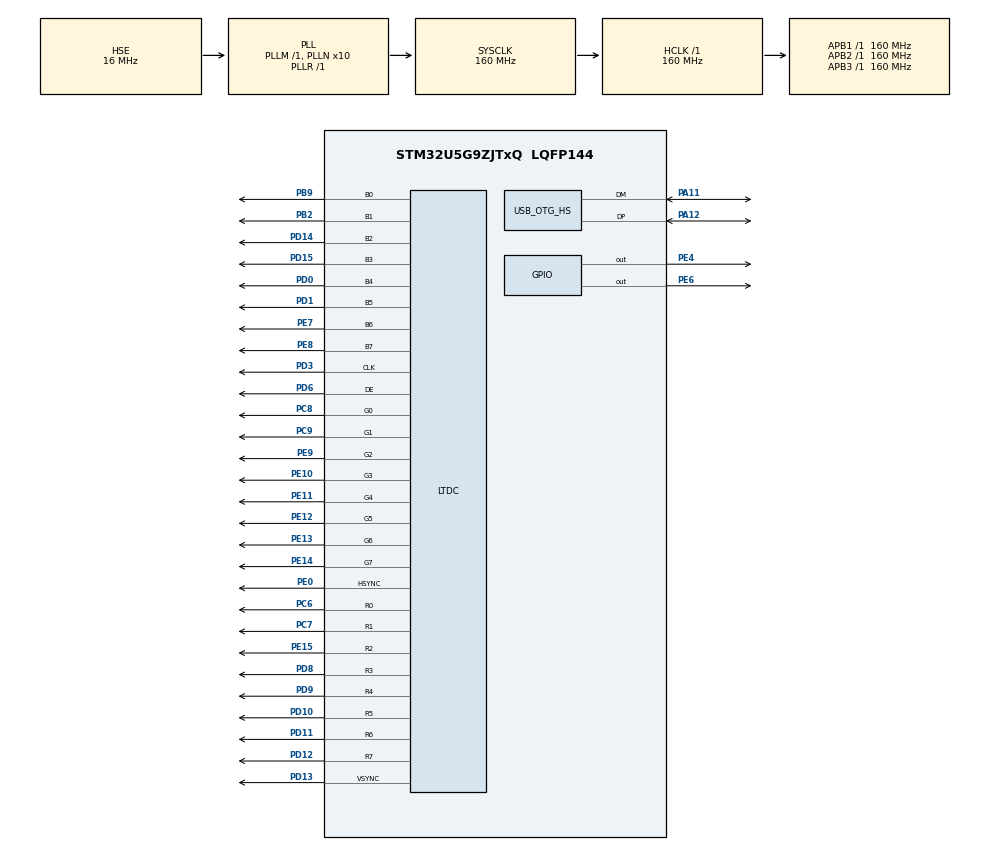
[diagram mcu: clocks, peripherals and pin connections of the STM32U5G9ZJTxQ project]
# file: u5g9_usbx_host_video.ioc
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CORTEX_M33_NS.userName=CORTEX_M33
LTDC.ActiveW=800
LTDC.Alpha0_L0=255
LTDC.Alpha_L0=255
LTDC.FBStartAdress_L0=0x300D0000
LTDC.Green_L0=255
LTDC.HBP=8
LTDC.HFP=8
LTDC.HSync=4
LTDC.ImageHeight_L0=240
LTDC.ImageWidth_L0=320
LTDC.Layers=0
LTDC.PixelFormat_L0=LTDC_PIXEL_FORMAT_RGB888
LTDC.VBP=8
LTDC.VFP=8
LTDC.WindowX1_L0=320
LTDC.WindowY1_L0=240
Mcu.Family=STM32U5
Mcu.Name=STM32U5G9ZJTxQ
Mcu.Package=LQFP144
NVIC.OTG_HS_IRQn=true\:0\:0\:false\:false\:true\:true\:true\:true
NVIC.PriorityGroup=NVIC_PRIORITYGROUP_4
PA11.Mode=Internal_Phy_Host
PA11.Signal=USB_OTG_HS_DM
PA12.Mode=Internal_Phy_Host
PA12.Signal=USB_OTG_HS_DP
PB2.Mode=RGB888
PB2.Signal=LTDC_B1
PB9.Mode=RGB888
PB9.Signal=LTDC_B0
PC6.Mode=RGB888
PC6.Signal=LTDC_R0
PC7.Mode=RGB888
PC7.Signal=LTDC_R1
PC8.Mode=RGB888
PC8.Signal=LTDC_G0
PC9.Mode=RGB888
PC9.Signal=LTDC_G1
PD0.Mode=RGB888
PD0.Signal=LTDC_B4
PD1.Mode=RGB888
PD1.Signal=LTDC_B5
PD10.Mode=RGB888
PD10.Signal=LTDC_R5
PD11.Mode=RGB888
PD11.Signal=LTDC_R6
PD12.Mode=RGB888
PD12.Signal=LTDC_R7
PD13.Mode=RGB888
PD13.Signal=LTDC_VSYNC
PD14.Mode=RGB888
PD14.Signal=LTDC_B2
PD15.Mode=RGB888
PD15.Signal=LTDC_B3
PD3.Mode=RGB888
PD3.Signal=LTDC_CLK
PD6.Mode=RGB888
PD6.Signal=LTDC_DE
PD8.Mode=RGB888
PD8.Signal=LTDC_R3
PD9.Mode=RGB888
PD9.Signal=LTDC_R4
PE0.Mode=RGB888
PE0.Signal=LTDC_HSYNC
PE10.Mode=RGB888
PE10.Signal=LTDC_G3
PE11.Mode=RGB888
PE11.Signal=LTDC_G4
PE12.Mode=RGB888
PE12.Signal=LTDC_G5
PE13.Mode=RGB888
PE13.Signal=LTDC_G6
PE14.Mode=RGB888
PE14.Signal=LTDC_G7
PE15.Mode=RGB888
PE15.Signal=LTDC_R2
PE4.PinState=GPIO_PIN_SET
PE4.Signal=GPIO_Output
PE6.GPIO_ModeDefaultOutputPP=GPIO_MODE_OUTPUT_OD
PE6.GPIO_PuPd=GPIO_NOPULL
PE6.PinState=GPIO_PIN_SET
PE6.Signal=GPIO_Output
PE7.Mode=RGB888
PE7.Signal=LTDC_B6
PE8.Mode=RGB888
PE8.Signal=LTDC_B7
PE9.Mode=RGB888
PE9.Signal=LTDC_G2
PH0-OSC_IN\ (PH0).Mode=HSE-External-Oscillator
PH0-OSC_IN\ (PH0).Signal=RCC_OSC_IN
PH1-OSC_OUT\ (PH1).Mode=HSE-External-Oscillator
PH1-OSC_OUT\ (PH1).Signal=RCC_OSC_OUT
ProjectManager.HeapSize=0x200
ProjectManager.StackSize=0x400
ProjectManager.TargetToolchain=STM32CubeIDE
RCC.ADCFreq_Value=16000000
RCC.AHBFreq_Value=160000000
RCC.APB1Freq_Value=160000000
RCC.APB1TimFreq_Value=160000000
RCC.APB2Freq_Value=160000000
RCC.APB2TimFreq_Value=160000000
RCC.APB3Freq_Value=160000000
RCC.CortexFreq_Value=160000000
RCC.EPOD_VALUE=16000000
RCC.HCLKFreq_Value=160000000
RCC.HSE_VALUE=16000000
RCC.HSI48_VALUE=48000000
RCC.HSI_VALUE=16000000
RCC.LSE_VALUE=32768
RCC.LSIDIV_VALUE=32000
RCC.MSI_VALUE=4000000
RCC.PLL1R=1
RCC.PLL2FRACN=0
RCC.PLL2M=3
RCC.PLL2N=100
RCC.PLL2R=21
RCC.PLL2Source=RCC_PLLSOURCE_HSE
RCC.PLLN=10
RCC.PLLSourceVirtual=RCC_PLLSOURCE_HSE
RCC.SYSCLKFreq_VALUE=160000000
RCC.SYSCLKSource=RCC_SYSCLKSOURCE_PLLCLK
RCC.USBPHYCLockSelection=RCC_USBPHYCLKSOURCE_HSE
RCC.VCOOutputFreq_Value=160000000
USBX.BSP.number=1
USBX.Core_System=1
USBX.USBX_HOST_SYS_SIZE=49152
USBX.UX_HOST_APP_MEM_POOL_SIZE_STANDALONE=65536
USBX.UX_Host_Controller=1
USBX.UX_Host_CoreStack=1
USBX.UX_Host_class_VIDEO=1
USBX.UX_MAX_HCD=2
USBX0.BSP.STBoard=false
USBX0.BSP.api=Unknown
USBX0.BSP.instance=USB_OTG_HS
USBX0.BSP.ip=USB_OTG_HS
USBX0.BSP.mode=Host_Only
USBX0.BSP.name=USBHost
USBX0.BSP.solution=USB_OTG_HS
USB_OTG_HS.VirtualMode=Host_HS
USB_OTG_HS.use_external_vbus=DISABLE
VP_LPBAMQUEUE_VS_QUEUE.Mode=QUEUEMODE
VP_LPBAM_VS_SIG1.Mode=SmartRun
VP_LPBAM_VS_SIG4.Mode=LPDMA1
VP_MEMORYMAP_VS_MEMORYMAP.Mode=CurAppReg
VP_PWR_VS_SECSignals.Mode=Security/Privilege
VP_USBX_Core_System.Mode=Core_System
VP_USBX_UX\ Host\ Controller_HS.Mode=UX_Host_Controller_HS
VP_USBX_UX\ Host\ CoreStack_HS.Mode=UX_Host_CoreStack_HS
VP_USBX_UX\ Host\ VIDEO_HS.Mode=UX_Host_class_VIDEO_HS
board=custom

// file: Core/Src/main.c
/* USER CODE BEGIN Header */
/**
  ******************************************************************************
  * @file           : main.c
  * @brief          : Main program body
  ******************************************************************************
  * @attention
  *
  * Copyright (c) 2024 STMicroelectronics.
  * All rights reserved.
  *
  * This software is licensed under terms that can be found in the LICENSE file
  * in the root directory of this software component.
  * If no LICENSE file comes with this software, it is provided AS-IS.
  *
  ******************************************************************************
  */
/* USER CODE END Header */
#include "main.h"
#include "app_usbx_host.h"

LTDC_HandleTypeDef hltdc;

HCD_HandleTypeDef hhcd_USB_OTG_HS;

void SystemClock_Config(void);
static void MX_GPIO_Init(void);
static void MX_USB_OTG_HS_HCD_Init(void);
static void MX_LTDC_Init(void);

int main(void)
{

  /* USER CODE BEGIN 1 */
memset(0x300D0000,0,320*240*3);
  /* USER CODE END 1 */

  /* MCU Configuration--------------------------------------------------------*/

  /* Reset of all peripherals, Initializes the Flash interface and the Systick. */
  HAL_Init();

  /* Configure the system clock */
  SystemClock_Config();

  /* Initialize all configured peripherals */
  MX_GPIO_Init();
  MX_USB_OTG_HS_HCD_Init();
  MX_USBX_Host_Init();
  MX_LTDC_Init();

  /* Infinite loop */
  /* USER CODE BEGIN WHILE */
  while (1)
  {
    ux_system_tasks_run();
    video_read();
    /* USER CODE END WHILE */

  }
}

void SystemClock_Config(void)
{
  RCC_OscInitTypeDef RCC_OscInitStruct = {0};
  RCC_ClkInitTypeDef RCC_ClkInitStruct = {0};

  /** Configure the main internal regulator output voltage
  */
  if (HAL_PWREx_ControlVoltageScaling(PWR_REGULATOR_VOLTAGE_SCALE1) != HAL_OK)
  {
    Error_Handler();
  }

  /** Initializes the CPU, AHB and APB buses clocks
  */
  RCC_OscInitStruct.OscillatorType = RCC_OSCILLATORTYPE_HSE;
  RCC_OscInitStruct.HSEState = RCC_HSE_ON;
  RCC_OscInitStruct.PLL.PLLState = RCC_PLL_ON;
  RCC_OscInitStruct.PLL.PLLSource = RCC_PLLSOURCE_HSE;
  RCC_OscInitStruct.PLL.PLLMBOOST = RCC_PLLMBOOST_DIV1;
  RCC_OscInitStruct.PLL.PLLM = 1;
  RCC_OscInitStruct.PLL.PLLN = 10;
  RCC_OscInitStruct.PLL.PLLP = 2;
  RCC_OscInitStruct.PLL.PLLQ = 2;
  RCC_OscInitStruct.PLL.PLLR = 1;
  RCC_OscInitStruct.PLL.PLLRGE = RCC_PLLVCIRANGE_1;
  RCC_OscInitStruct.PLL.PLLFRACN = 0;
  if (HAL_RCC_OscConfig(&RCC_OscInitStruct) != HAL_OK)
  {
    Error_Handler();
  }

  /** Initializes the CPU, AHB and APB buses clocks
  */
  RCC_ClkInitStruct.ClockType = RCC_CLOCKTYPE_HCLK|RCC_CLOCKTYPE_SYSCLK
                              |RCC_CLOCKTYPE_PCLK1|RCC_CLOCKTYPE_PCLK2
                              |RCC_CLOCKTYPE_PCLK3;
  RCC_ClkInitStruct.SYSCLKSource = RCC_SYSCLKSOURCE_PLLCLK;
  RCC_ClkInitStruct.AHBCLKDivider = RCC_SYSCLK_DIV1;
  RCC_ClkInitStruct.APB1CLKDivider = RCC_HCLK_DIV1;
  RCC_ClkInitStruct.APB2CLKDivider = RCC_HCLK_DIV1;
  RCC_ClkInitStruct.APB3CLKDivider = RCC_HCLK_DIV1;

  if (HAL_RCC_ClockConfig(&RCC_ClkInitStruct, FLASH_LATENCY_4) != HAL_OK)
  {
    Error_Handler();
  }
}

static void MX_LTDC_Init(void)
{

  LTDC_LayerCfgTypeDef pLayerCfg = {0};

  hltdc.Instance = LTDC;
  hltdc.Init.HSPolarity = LTDC_HSPOLARITY_AL;
  hltdc.Init.VSPolarity = LTDC_VSPOLARITY_AL;
  hltdc.Init.DEPolarity = LTDC_DEPOLARITY_AL;
  hltdc.Init.PCPolarity = LTDC_PCPOLARITY_IPC;
  hltdc.Init.HorizontalSync = 3;
  hltdc.Init.VerticalSync = 3;
  hltdc.Init.AccumulatedHBP = 11;
  hltdc.Init.AccumulatedVBP = 11;
  hltdc.Init.AccumulatedActiveW = 811;
  hltdc.Init.AccumulatedActiveH = 491;
  hltdc.Init.TotalWidth = 819;
  hltdc.Init.TotalHeigh = 499;
  hltdc.Init.Backcolor.Blue = 0;
  hltdc.Init.Backcolor.Green = 0;
  hltdc.Init.Backcolor.Red = 0;
  if (HAL_LTDC_Init(&hltdc) != HAL_OK)
  {
    Error_Handler();
  }
  pLayerCfg.WindowX0 = 0;
  pLayerCfg.WindowX1 = 320;
  pLayerCfg.WindowY0 = 0;
  pLayerCfg.WindowY1 = 240;
  pLayerCfg.PixelFormat = LTDC_PIXEL_FORMAT_RGB888;
  pLayerCfg.Alpha = 255;
  pLayerCfg.Alpha0 = 255;
  pLayerCfg.BlendingFactor1 = LTDC_BLENDING_FACTOR1_CA;
  pLayerCfg.BlendingFactor2 = LTDC_BLENDING_FACTOR2_CA;
  pLayerCfg.FBStartAdress = 0x300D0000;
  pLayerCfg.ImageWidth = 320;
  pLayerCfg.ImageHeight = 240;
  pLayerCfg.Backcolor.Blue = 0;
  pLayerCfg.Backcolor.Green = 255;
  pLayerCfg.Backcolor.Red = 0;
  if (HAL_LTDC_ConfigLayer(&hltdc, &pLayerCfg, 0) != HAL_OK)
  {
    Error_Handler();
  }

}

static void MX_USB_OTG_HS_HCD_Init(void)
{

  hhcd_USB_OTG_HS.Instance = USB_OTG_HS;
  hhcd_USB_OTG_HS.Init.Host_channels = 16;
  hhcd_USB_OTG_HS.Init.speed = HCD_SPEED_HIGH;
  hhcd_USB_OTG_HS.Init.dma_enable = DISABLE;
  hhcd_USB_OTG_HS.Init.phy_itface = USB_OTG_HS_EMBEDDED_PHY;
  hhcd_USB_OTG_HS.Init.Sof_enable = DISABLE;
  hhcd_USB_OTG_HS.Init.low_power_enable = DISABLE;
  hhcd_USB_OTG_HS.Init.use_external_vbus = DISABLE;
  if (HAL_HCD_Init(&hhcd_USB_OTG_HS) != HAL_OK)
  {
    Error_Handler();
  }

}

static void MX_GPIO_Init(void)
{
  GPIO_InitTypeDef GPIO_InitStruct = {0};

  /* GPIO Ports Clock Enable */
  __HAL_RCC_GPIOE_CLK_ENABLE();
  __HAL_RCC_GPIOH_CLK_ENABLE();
  __HAL_RCC_GPIOB_CLK_ENABLE();
  __HAL_RCC_GPIOD_CLK_ENABLE();
  __HAL_RCC_GPIOC_CLK_ENABLE();
  __HAL_RCC_GPIOA_CLK_ENABLE();

  /*Configure GPIO pin Output Level */
  HAL_GPIO_WritePin(GPIOE, GPIO_PIN_4|GPIO_PIN_6, GPIO_PIN_SET);

  /*Configure GPIO pin : PE4 */
  GPIO_InitStruct.Pin = GPIO_PIN_4;
  GPIO_InitStruct.Mode = GPIO_MODE_OUTPUT_PP;
  GPIO_InitStruct.Pull = GPIO_NOPULL;
  GPIO_InitStruct.Speed = GPIO_SPEED_FREQ_LOW;
  HAL_GPIO_Init(GPIOE, &GPIO_InitStruct);

  /*Configure GPIO pin : PE6 */
  GPIO_InitStruct.Pin = GPIO_PIN_6;
  GPIO_InitStruct.Mode = GPIO_MODE_OUTPUT_OD;
  GPIO_InitStruct.Pull = GPIO_NOPULL;
  GPIO_InitStruct.Speed = GPIO_SPEED_FREQ_LOW;
  HAL_GPIO_Init(GPIOE, &GPIO_InitStruct);

}

void Error_Handler(void)
{
  __disable_irq();
  while (1)
  {
  }
}
